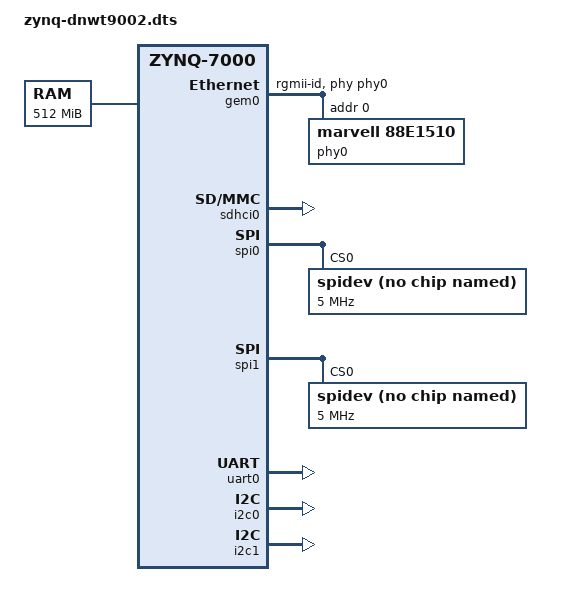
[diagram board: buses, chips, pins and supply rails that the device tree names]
/*
 * CAUTION: This file is automatically generated by Xilinx.
 * Version:  
 * Today is: Thu Mar 30 15:14:11 2023
 */


/dts-v1/;
#include "zynq-7000-sys.dtsi"
/ {
	
	chosen {
		bootargs = "earlycon";
		stdout-path = "serial0:115200n8";
	};
	aliases {
		ethernet0 = &gem0;
		serial0 = &uart0;		
		i2c0 = &i2c0;
		i2c1 = &i2c1;
	};
	memory {
		device_type = "memory";
		reg = <0x0 0x20000000>;
	};

	reserved-memory {
		#address-cells = <1>;
		#size-cells = <1>;
		ranges;

		reserved: buffer@18000000 {
			reg = <0x18000000 0x4000000>;
		};
	};

	ccma {
		compatible = "stc,ccma";
		memory-region = <&reserved>;
	};

	reserved-driver@0 {
		compatible = "xlnx,reserved-memory";
		memory-region = <&reserved>;
	};

	cpus {
		cpu@0 {
			operating-points = <666666 1000000 333333 1000000>;
		};
	};
};
/* ETH PHY */
&gem0 {
    status = "okay";
    phy-mode = "rgmii-id";
    phy-handle = <&phy0>;
    phy0: phy@0 {
        compatible = "marvell,88e1510";
        device_type = "ethernet-phy";
        reg = <0>;
    };
};

&intc {
	num_cpus = <2>;
	num_interrupts = <96>;
};

&sdhci0 {
	u-boot,dm-pre-reloc;
	status = "okay";
	xlnx,has-cd = <0x0>;
	xlnx,has-power = <0x0>;
	xlnx,has-wp = <0x0>;
};
&spi0 {
	bits-per-word = <8>;
	is-decoded-cs = <0>;
	num-cs = <1>;
	status = "okay";

	spidev@0x00 {
		compatible = "spidev";
		spi-max-frequency = <5000000>;
		reg = <0>;
	};
};

&spi1 {
	bits-per-word = <8>;
	is-decoded-cs = <0>;
	num-cs = <1>;
	status = "okay";

	spidev@0x00 {
		compatible = "spidev";
		spi-max-frequency = <5000000>;
		reg = <0>;
	};
};

&uart0 {
	u-boot,dm-pre-reloc;
	cts-override ;
	device_type = "serial";
	port-number = <0>;
	status = "okay";
};

&i2c0 {
	status = "okay";
};

&i2c1 {
	status = "okay";
};


&clkc {
	fclk-enable = <0x1>;
	ps-clk-frequency = <33333333>;
};
